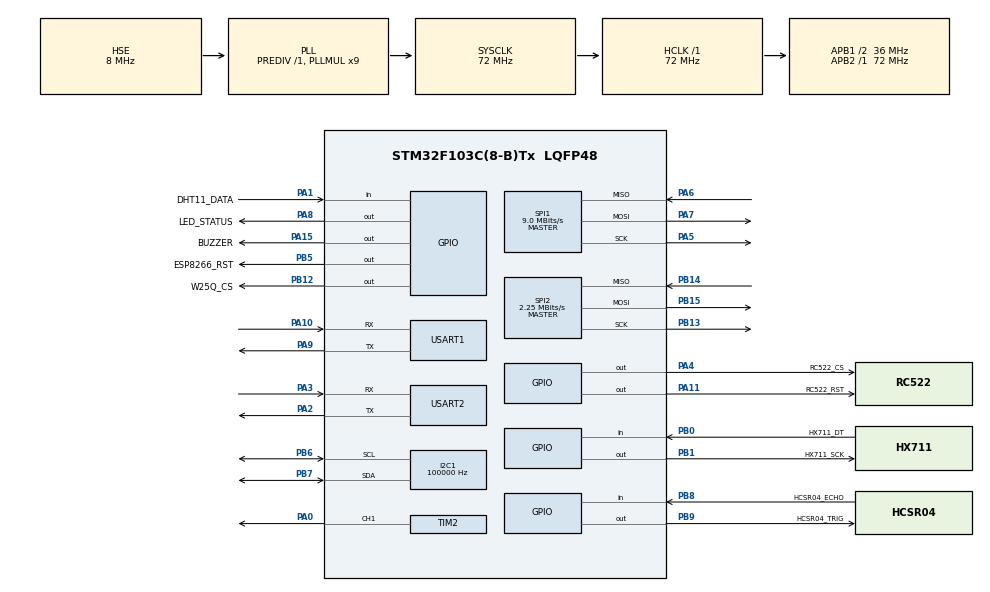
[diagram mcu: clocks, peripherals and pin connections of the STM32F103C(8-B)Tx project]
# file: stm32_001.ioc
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FREERTOS.BinarySemaphores01=SensorReadySem,Dynamic,NULL,Depleted
FREERTOS.Mutexes01=SpiMutex,Dynamic,NULL,Available
FREERTOS.Queues01=RfidEventQueue,8,RfidEvent_t,0,Dynamic,NULL,NULL;SensorDataQueue,8,SensorData_t,0,Dynamic,NULL,NULL;StorageQueue,10,StorageRecord_t,0,Dynamic,NULL,NULL;MqttPublishQueue,8,StorageRecord_t,0,Dynamic,NULL,NULL;DeviceCommandQueue,4,DeviceCommand_t,0,Dynamic,NULL,NULL
FREERTOS.Tasks01=USART1Task,24,128,StartUSART1Task,Default,NULL,Dynamic,NULL,NULL;ESP8266Task,32,512,StartESP8266Task,Default,NULL,Dynamic,NULL,NULL;SensorTask,24,256,StartSensorTask,Default,NULL,Dynamic,NULL,NULL;RfidTask,24,256,StartRfidTask,Default,NULL,Dynamic,NULL,NULL;TraceTask,32,384,StartTraceTask,Default,NULL,Dynamic,NULL,NULL;StorageTask,24,384,StartStorageTask,Default,NULL,Dynamic,NULL,NULL;HealthTask,40,256,StartHealthTask,Default,NULL,Dynamic,NULL,NULL
FREERTOS.configTIMER_QUEUE_LENGTH=10
FREERTOS.configTIMER_TASK_PRIORITY=1
FREERTOS.configTIMER_TASK_STACK_DEPTH=256
FREERTOS.configTOTAL_HEAP_SIZE=12288
FREERTOS.configUSE_COUNTING_SEMAPHORES=1
FREERTOS.configUSE_MUTEXES=1
FREERTOS.configUSE_TASK_NOTIFICATIONS=1
FREERTOS.configUSE_TIMERS=1
I2C1.AddressingMode=I2C_ADDRESSINGMODE_7BIT
I2C1.ClockSpeed=100000
I2C1.DualAddressMode=I2C_DUALADDRESS_DISABLE
I2C1.GeneralCallMode=I2C_GENERALCALL_DISABLE
I2C1.NoStretchMode=I2C_NOSTRETCH_DISABLE
I2C1.OwnAddress1=0
IWDG.Prescaler=IWDG_PRESCALER_64
IWDG.Reload=2500
Mcu.Family=STM32F1
Mcu.Name=STM32F103C(8-B)Tx
Mcu.Package=LQFP48
NVIC.PriorityGroup=NVIC_PRIORITYGROUP_4
NVIC.TIM3_IRQn=true\:15\:0\:false\:false\:true\:false\:false\:true\:true
NVIC.TimeBase=TIM3_IRQn
NVIC.TimeBaseIP=TIM3
NVIC.USART1_IRQn=true\:5\:0\:false\:false\:true\:true\:true\:true\:true
NVIC.USART2_IRQn=true\:5\:0\:false\:false\:true\:true\:true\:true\:true
PA0-WKUP.Signal=S_TIM2_CH1_ETR
PA1.GPIO_Label=DHT11_DATA
PA1.GPIO_PuPd=GPIO_NOPULL
PA1.Signal=GPIO_Input
PA10.Mode=Asynchronous
PA10.Signal=USART1_RX
PA11.GPIO_Label=RC522_RST
PA11.GPIO_ModeDefaultOutputPP=GPIO_MODE_OUTPUT_PP
PA11.GPIO_Speed=GPIO_SPEED_FREQ_LOW
PA11.PinState=GPIO_PIN_SET
PA11.Signal=GPIO_Output
PA13.Mode=Serial_Wire
PA13.Signal=SYS_JTMS-SWDIO
PA14.Mode=Serial_Wire
PA14.Signal=SYS_JTCK-SWCLK
PA15.GPIO_Label=BUZZER
PA15.GPIO_ModeDefaultOutputPP=GPIO_MODE_OUTPUT_PP
PA15.GPIO_Speed=GPIO_SPEED_FREQ_LOW
PA15.PinState=GPIO_PIN_RESET
PA15.Signal=GPIO_Output
PA2.Mode=Asynchronous
PA2.Signal=USART2_TX
PA3.Mode=Asynchronous
PA3.Signal=USART2_RX
PA4.GPIO_Label=RC522_CS
PA4.GPIO_ModeDefaultOutputPP=GPIO_MODE_OUTPUT_PP
PA4.GPIO_Speed=GPIO_SPEED_FREQ_HIGH
PA4.PinState=GPIO_PIN_SET
PA4.Signal=GPIO_Output
PA5.Mode=Full_Duplex_Master
PA5.Signal=SPI1_SCK
PA6.Mode=Full_Duplex_Master
PA6.Signal=SPI1_MISO
PA7.Mode=Full_Duplex_Master
PA7.Signal=SPI1_MOSI
PA8.GPIO_Label=LED_STATUS
PA8.GPIO_ModeDefaultOutputPP=GPIO_MODE_OUTPUT_PP
PA8.GPIO_Speed=GPIO_SPEED_FREQ_LOW
PA8.PinState=GPIO_PIN_RESET
PA8.Signal=GPIO_Output
PA9.Mode=Asynchronous
PA9.Signal=USART1_TX
PB0.GPIO_Label=HX711_DT
PB0.GPIO_PuPd=GPIO_NOPULL
PB0.Signal=GPIO_Input
PB1.GPIO_Label=HX711_SCK
PB1.GPIO_ModeDefaultOutputPP=GPIO_MODE_OUTPUT_PP
PB1.GPIO_Speed=GPIO_SPEED_FREQ_LOW
PB1.PinState=GPIO_PIN_RESET
PB1.Signal=GPIO_Output
PB12.GPIO_Label=W25Q_CS
PB12.GPIO_ModeDefaultOutputPP=GPIO_MODE_OUTPUT_PP
PB12.GPIO_Speed=GPIO_SPEED_FREQ_HIGH
PB12.PinState=GPIO_PIN_SET
PB12.Signal=GPIO_Output
PB13.Mode=Full_Duplex_Master
PB13.Signal=SPI2_SCK
PB14.Mode=Full_Duplex_Master
PB14.Signal=SPI2_MISO
PB15.Mode=Full_Duplex_Master
PB15.Signal=SPI2_MOSI
PB5.GPIO_Label=ESP8266_RST
PB5.GPIO_ModeDefaultOutputPP=GPIO_MODE_OUTPUT_PP
PB5.GPIO_Speed=GPIO_SPEED_FREQ_LOW
PB5.PinState=GPIO_PIN_SET
PB5.Signal=GPIO_Output
PB6.Mode=I2C
PB6.Signal=I2C1_SCL
PB7.Mode=I2C
PB7.Signal=I2C1_SDA
PB8.GPIO_Label=HCSR04_ECHO
PB8.GPIO_PuPd=GPIO_NOPULL
PB8.Signal=GPIO_Input
PB9.GPIO_Label=HCSR04_TRIG
PB9.GPIO_ModeDefaultOutputPP=GPIO_MODE_OUTPUT_PP
PB9.GPIO_Speed=GPIO_SPEED_FREQ_LOW
PB9.PinState=GPIO_PIN_RESET
PB9.Signal=GPIO_Output
PD0-OSC_IN.Mode=HSE-External-Oscillator
PD0-OSC_IN.Signal=RCC_OSC_IN
PD1-OSC_OUT.Mode=HSE-External-Oscillator
PD1-OSC_OUT.Signal=RCC_OSC_OUT
ProjectManager.HeapSize=0x200
ProjectManager.StackSize=0x400
ProjectManager.TargetToolchain=MDK-ARM V5.32
RCC.AHBFreq_Value=72000000
RCC.APB1CLKDivider=RCC_HCLK_DIV2
RCC.APB1Freq_Value=36000000
RCC.APB1TimFreq_Value=72000000
RCC.APB2Freq_Value=72000000
RCC.APB2TimFreq_Value=72000000
RCC.HCLKFreq_Value=72000000
RCC.PLLMUL=RCC_PLL_MUL9
RCC.PLLSourceVirtual=RCC_PLLSOURCE_HSE
RCC.SYSCLKFreq_VALUE=72000000
RCC.SYSCLKSource=RCC_SYSCLKSOURCE_PLLCLK
RCC.USBFreq_Value=72000000
SH.S_TIM2_CH1_ETR.0=TIM2_CH1,PWM Generation1 CH1
SPI1.BaudRatePrescaler=SPI_BAUDRATEPRESCALER_8
SPI1.CLKPhase=SPI_PHASE_1EDGE
SPI1.CLKPolarity=SPI_POLARITY_LOW
SPI1.CRCCalculation=SPI_CRCCALCULATION_DISABLE
SPI1.CalculateBaudRate=9.0 MBits/s
SPI1.DataSize=SPI_DATASIZE_8BIT
SPI1.Direction=SPI_DIRECTION_2LINES
SPI1.FirstBit=SPI_FIRSTBIT_MSB
SPI1.Mode=SPI_MODE_MASTER
SPI1.NSS=SPI_NSS_SOFT
SPI1.VirtualType=VM_MASTER
SPI2.BaudRatePrescaler=SPI_BAUDRATEPRESCALER_16
SPI2.CLKPhase=SPI_PHASE_1EDGE
SPI2.CLKPolarity=SPI_POLARITY_LOW
SPI2.CRCCalculation=SPI_CRCCALCULATION_DISABLE
SPI2.CalculateBaudRate=2.25 MBits/s
SPI2.DataSize=SPI_DATASIZE_8BIT
SPI2.Direction=SPI_DIRECTION_2LINES
SPI2.FirstBit=SPI_FIRSTBIT_MSB
SPI2.Mode=SPI_MODE_MASTER
SPI2.NSS=SPI_NSS_SOFT
SPI2.VirtualType=VM_MASTER
SYS.Debug=Serial_Wire
TIM2.AutoReloadPreload=TIM_AUTORELOAD_PRELOAD_DISABLE
TIM2.Channel-PWM\ Generation1\ CH1=TIM_CHANNEL_1
TIM2.ClockDivision=TIM_CLOCKDIVISION_DIV1
TIM2.CounterMode=TIM_COUNTERMODE_UP
TIM2.Period=19999
TIM2.Prescaler=71
TIM2.Pulse-PWM\ Generation1\ CH1=1500
USART1.VirtualMode=VM_ASYNC
USART2.VirtualMode=VM_ASYNC
VP_FREERTOS_VS_CMSIS_V2.Mode=CMSIS_V2
VP_IWDG_VS_IWDG.Mode=IWDG_Activate
VP_SYS_VS_tim3.Mode=TIM3
VP_TIM2_VS_ClockSourceINT.Mode=Internal
board=custom

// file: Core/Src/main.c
/* USER CODE BEGIN Header */
/**
  ******************************************************************************
  * @file           : main.c
  * @brief          : Main program body
  ******************************************************************************
  * @attention
  *
  * Copyright (c) 2026 STMicroelectronics.
  * All rights reserved.
  *
  * This software is licensed under terms that can be found in the LICENSE file
  * in the root directory of this software component.
  * If no LICENSE file comes with this software, it is provided AS-IS.
  *
  ******************************************************************************
  */
/* USER CODE END Header */
#include "main.h"
#include "cmsis_os.h"
#include "i2c.h"
#include "iwdg.h"
#include "spi.h"
#include "tim.h"
#include "usart.h"
#include "gpio.h"

void SystemClock_Config(void);
void MX_FREERTOS_Init(void);

int main(void)
{

  /* MCU Configuration--------------------------------------------------------*/

  /* Reset of all peripherals, Initializes the Flash interface and the Systick. */
  HAL_Init();

  /* Configure the system clock */
  SystemClock_Config();

  /* Initialize all configured peripherals */
  MX_GPIO_Init();
  MX_I2C1_Init();
  MX_SPI1_Init();
  MX_SPI2_Init();
  MX_TIM2_Init();
  MX_USART1_UART_Init();
  MX_USART2_UART_Init();
  MX_IWDG_Init();

  /* Init scheduler */
  osKernelInitialize();  /* Call init function for freertos objects (in cmsis_os2.c) */
  MX_FREERTOS_Init();

  /* Start scheduler */
  osKernelStart();

  /* We should never get here as control is now taken by the scheduler */

  /* Infinite loop */
  while (1)
  {

  }
}

void SystemClock_Config(void)
{
  RCC_OscInitTypeDef RCC_OscInitStruct = {0};
  RCC_ClkInitTypeDef RCC_ClkInitStruct = {0};

  /** Initializes the RCC Oscillators according to the specified parameters
  * in the RCC_OscInitTypeDef structure.
  */
  RCC_OscInitStruct.OscillatorType = RCC_OSCILLATORTYPE_LSI|RCC_OSCILLATORTYPE_HSE;
  RCC_OscInitStruct.HSEState = RCC_HSE_ON;
  RCC_OscInitStruct.HSEPredivValue = RCC_HSE_PREDIV_DIV1;
  RCC_OscInitStruct.HSIState = RCC_HSI_ON;
  RCC_OscInitStruct.LSIState = RCC_LSI_ON;
  RCC_OscInitStruct.PLL.PLLState = RCC_PLL_ON;
  RCC_OscInitStruct.PLL.PLLSource = RCC_PLLSOURCE_HSE;
  RCC_OscInitStruct.PLL.PLLMUL = RCC_PLL_MUL9;
  if (HAL_RCC_OscConfig(&RCC_OscInitStruct) != HAL_OK)
  {
    Error_Handler();
  }

  /** Initializes the CPU, AHB and APB buses clocks
  */
  RCC_ClkInitStruct.ClockType = RCC_CLOCKTYPE_HCLK|RCC_CLOCKTYPE_SYSCLK
                              |RCC_CLOCKTYPE_PCLK1|RCC_CLOCKTYPE_PCLK2;
  RCC_ClkInitStruct.SYSCLKSource = RCC_SYSCLKSOURCE_PLLCLK;
  RCC_ClkInitStruct.AHBCLKDivider = RCC_SYSCLK_DIV1;
  RCC_ClkInitStruct.APB1CLKDivider = RCC_HCLK_DIV2;
  RCC_ClkInitStruct.APB2CLKDivider = RCC_HCLK_DIV1;

  if (HAL_RCC_ClockConfig(&RCC_ClkInitStruct, FLASH_LATENCY_2) != HAL_OK)
  {
    Error_Handler();
  }
}

void HAL_TIM_PeriodElapsedCallback(TIM_HandleTypeDef *htim)
{
  if (htim->Instance == TIM3)
  {
    HAL_IncTick();
  }
}

void Error_Handler(void)
{
  __disable_irq();
  while (1)
  {
  }
}

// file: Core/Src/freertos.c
/* USER CODE BEGIN Header */
/**
  ******************************************************************************
  * File Name          : freertos.c
  * Description        : FreeRTOS object creation and task entry dispatch.
  ******************************************************************************
  */
/* USER CODE END Header */

#include "FreeRTOS.h"
#include "task.h"
#include "main.h"
#include "cmsis_os.h"

/* USER CODE BEGIN Includes */
#include "app_types.h"
#include "app_tasks.h"
#include "mqtt_at.h"
/* USER CODE END Includes */

/* USER CODE BEGIN Variables */
/* TraceTask -> ESP8266Task：反馈舵机命令已在设备端真正执行。 */
osMessageQueueId_t DeviceCommandResultQueueHandle;
/* DS3231 的 I2C1 访问锁，避免多个任务并发调用 HAL I2C。 */
osMutexId_t RtcMutexHandle;
/* USER CODE END Variables */
/* Definitions for USART1Task */
osThreadId_t USART1TaskHandle;
const osThreadAttr_t USART1Task_attributes = {
  .name = "USART1Task",
  .stack_size = 128 * 4,
  .priority = (osPriority_t) osPriorityNormal,
};
/* Definitions for ESP8266Task */
osThreadId_t ESP8266TaskHandle;
const osThreadAttr_t ESP8266Task_attributes = {
  .name = "ESP8266Task",
  .stack_size = 512 * 4,
  .priority = (osPriority_t) osPriorityAboveNormal,
};
/* Definitions for SensorTask */
osThreadId_t SensorTaskHandle;
const osThreadAttr_t SensorTask_attributes = {
  .name = "SensorTask",
  .stack_size = 256 * 4,
  .priority = (osPriority_t) osPriorityNormal,
};
/* Definitions for RfidTask */
osThreadId_t RfidTaskHandle;
const osThreadAttr_t RfidTask_attributes = {
  .name = "RfidTask",
  .stack_size = 256 * 4,
  .priority = (osPriority_t) osPriorityNormal,
};
/* Definitions for TraceTask */
osThreadId_t TraceTaskHandle;
const osThreadAttr_t TraceTask_attributes = {
  .name = "TraceTask",
  .stack_size = 384 * 4,
  .priority = (osPriority_t) osPriorityAboveNormal,
};
/* Definitions for StorageTask */
osThreadId_t StorageTaskHandle;
const osThreadAttr_t StorageTask_attributes = {
  .name = "StorageTask",
  .stack_size = 384 * 4,
  .priority = (osPriority_t) osPriorityNormal,
};
/* Definitions for HealthTask */
osThreadId_t HealthTaskHandle;
const osThreadAttr_t HealthTask_attributes = {
  .name = "HealthTask",
  .stack_size = 256 * 4,
  .priority = (osPriority_t) osPriorityHigh,
};
/* Definitions for RfidEventQueue */
osMessageQueueId_t RfidEventQueueHandle;
const osMessageQueueAttr_t RfidEventQueue_attributes = {
  .name = "RfidEventQueue"
};
/* Definitions for SensorDataQueue */
osMessageQueueId_t SensorDataQueueHandle;
const osMessageQueueAttr_t SensorDataQueue_attributes = {
  .name = "SensorDataQueue"
};
/* Definitions for StorageQueue */
osMessageQueueId_t StorageQueueHandle;
const osMessageQueueAttr_t StorageQueue_attributes = {
  .name = "StorageQueue"
};
/* Definitions for MqttPublishQueue */
osMessageQueueId_t MqttPublishQueueHandle;
const osMessageQueueAttr_t MqttPublishQueue_attributes = {
  .name = "MqttPublishQueue"
};
/* Definitions for DeviceCommandQueue */
osMessageQueueId_t DeviceCommandQueueHandle;
const osMessageQueueAttr_t DeviceCommandQueue_attributes = {
  .name = "DeviceCommandQueue"
};
/* Definitions for SpiMutex */
osMutexId_t SpiMutexHandle;
const osMutexAttr_t SpiMutex_attributes = {
  .name = "SpiMutex"
};
/* Definitions for SensorReadySem */
osSemaphoreId_t SensorReadySemHandle;
const osSemaphoreAttr_t SensorReadySem_attributes = {
  .name = "SensorReadySem"
};

void StartUSART1Task(void *argument);
void StartESP8266Task(void *argument);
void StartSensorTask(void *argument);
void StartRfidTask(void *argument);
void StartTraceTask(void *argument);
void StartStorageTask(void *argument);
void StartHealthTask(void *argument);

void MX_FREERTOS_Init(void); /* (MISRA C 2004 rule 8.1) */

void MX_FREERTOS_Init(void) {
  /* Create the mutex(es) */
  /* creation of SpiMutex */
  SpiMutexHandle = osMutexNew(&SpiMutex_attributes);

  /* USER CODE BEGIN RTOS_MUTEX */
  RtcMutexHandle = osMutexNew(NULL);
  /* USER CODE END RTOS_MUTEX */

  /* Create the semaphores(s) */
  /* creation of SensorReadySem */
  SensorReadySemHandle = osSemaphoreNew(1, 0, &SensorReadySem_attributes);

  /* Create the queue(s) */
  /* creation of RfidEventQueue */
  RfidEventQueueHandle = osMessageQueueNew (8, sizeof(RfidEvent_t), &RfidEventQueue_attributes);

  /* creation of SensorDataQueue */
  SensorDataQueueHandle = osMessageQueueNew (8, sizeof(SensorData_t), &SensorDataQueue_attributes);

  /* creation of StorageQueue */
  StorageQueueHandle = osMessageQueueNew (10, sizeof(StorageRecord_t), &StorageQueue_attributes);

  /* creation of MqttPublishQueue */
  MqttPublishQueueHandle = osMessageQueueNew (8, sizeof(StorageRecord_t), &MqttPublishQueue_attributes);

  /* creation of DeviceCommandQueue */
  DeviceCommandQueueHandle = osMessageQueueNew (4, sizeof(DeviceCommand_t), &DeviceCommandQueue_attributes);

  /* USER CODE BEGIN RTOS_QUEUES */
  DeviceCommandResultQueueHandle = osMessageQueueNew(4, sizeof(DeviceCommand_t), NULL);
  /* USER CODE END RTOS_QUEUES */

  /* Create the thread(s) */
  /* creation of USART1Task */
  USART1TaskHandle = osThreadNew(StartUSART1Task, NULL, &USART1Task_attributes);

  /* creation of ESP8266Task */
  ESP8266TaskHandle = osThreadNew(StartESP8266Task, NULL, &ESP8266Task_attributes);

  /* creation of SensorTask */
  SensorTaskHandle = osThreadNew(StartSensorTask, NULL, &SensorTask_attributes);

  /* creation of RfidTask */
  RfidTaskHandle = osThreadNew(StartRfidTask, NULL, &RfidTask_attributes);

  /* creation of TraceTask */
  TraceTaskHandle = osThreadNew(StartTraceTask, NULL, &TraceTask_attributes);

  /* creation of StorageTask */
  StorageTaskHandle = osThreadNew(StartStorageTask, NULL, &StorageTask_attributes);

  /* creation of HealthTask */
  HealthTaskHandle = osThreadNew(StartHealthTask, NULL, &HealthTask_attributes);

}

void StartUSART1Task(void *argument)
{
  /* USER CODE BEGIN StartUSART1Task */
  AppTask_RunUsart1(argument);
  /* USER CODE END StartUSART1Task */
}

void StartESP8266Task(void *argument)
{
  /* USER CODE BEGIN StartESP8266Task */
  MqttAt_RunTask(argument);
  /* USER CODE END StartESP8266Task */
}

void StartSensorTask(void *argument)
{
  /* USER CODE BEGIN StartSensorTask */
  AppTask_RunSensor(argument);
  /* USER CODE END StartSensorTask */
}

void StartRfidTask(void *argument)
{
  /* USER CODE BEGIN StartRfidTask */
  AppTask_RunRfid(argument);
  /* USER CODE END StartRfidTask */
}

void StartTraceTask(void *argument)
{
  /* USER CODE BEGIN StartTraceTask */
  AppTask_RunTrace(argument);
  /* USER CODE END StartTraceTask */
}

void StartStorageTask(void *argument)
{
  /* USER CODE BEGIN StartStorageTask */
  AppTask_RunStorage(argument);
  /* USER CODE END StartStorageTask */
}

void StartHealthTask(void *argument)
{
  /* USER CODE BEGIN StartHealthTask */
  AppTask_RunHealth(argument);
  /* USER CODE END StartHealthTask */
}
